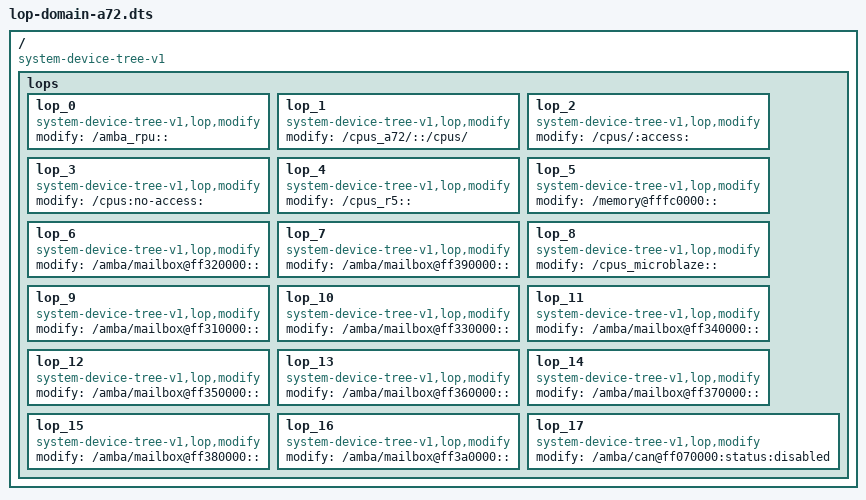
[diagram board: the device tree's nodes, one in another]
/*
 * Copyright (c) 2019,2020 Xilinx Inc. All rights reserved.
 *
 * Author:
 *       Bruce Ashfield <bruce.ashfield@xilinx.com>
 *
 * SPDX-License-Identifier: BSD-3-Clause
 */

/dts-v1/;

/ {
        compatible = "system-device-tree-v1";
        lops {
                // compatible = "system-device-tree-v1,lop";
                lop_0 {
                        // modify to "nothing", is a remove operation
                        compatible = "system-device-tree-v1,lop,modify";
                        modify = "/amba_rpu::";
                };
                lop_1 {
                        // node name modify
                        compatible = "system-device-tree-v1,lop,modify";
                        modify = "/cpus_a72/::/cpus/";
                };
                lop_2 {
                        compatible = "system-device-tree-v1,lop,modify";
                        // format is: "path":"property":"replacement"
                        //    - modify to "nothing", is a remove operation
                        //    - modify with no property is node operation (rename or remove)
                        modify = "/cpus/:access:";
                };
                lop_3 {
                        // modify to "nothing", is a remove operation
                        compatible = "system-device-tree-v1,lop,modify";
                        modify = "/cpus:no-access:";
                };
                lop_4 {
                        // modify to "nothing", is a remove operation
                        compatible = "system-device-tree-v1,lop,modify";
                        modify = "/cpus_r5::";
                };
                lop_5 {
                        // modify to "nothing", is a remove operation
                        compatible = "system-device-tree-v1,lop,modify";
                        modify = "/memory@fffc0000::";
                };
		lop_6 {
                        compatible = "system-device-tree-v1,lop,modify";
                        modify = "/amba/mailbox@ff320000::";
                };
		lop_7 {
                        compatible = "system-device-tree-v1,lop,modify";
                        modify = "/amba/mailbox@ff390000::";
                };
                lop_8 {
                        // modify to "nothing", is a remove operation
                        compatible = "system-device-tree-v1,lop,modify";
                        modify = "/cpus_microblaze::";
                };
		lop_9 {
                        compatible = "system-device-tree-v1,lop,modify";
                        modify = "/amba/mailbox@ff310000::";
                };
		lop_10 {
                        compatible = "system-device-tree-v1,lop,modify";
                        modify = "/amba/mailbox@ff330000::";
                };
		lop_11 {
                        compatible = "system-device-tree-v1,lop,modify";
                        modify = "/amba/mailbox@ff340000::";
                };
		lop_12 {
                        compatible = "system-device-tree-v1,lop,modify";
                        modify = "/amba/mailbox@ff350000::";
                };
		lop_13 {
                        compatible = "system-device-tree-v1,lop,modify";
                        modify = "/amba/mailbox@ff360000::";
                };
		lop_14 {
                        compatible = "system-device-tree-v1,lop,modify";
                        modify = "/amba/mailbox@ff370000::";
                };
		lop_15 {
                        compatible = "system-device-tree-v1,lop,modify";
                        modify = "/amba/mailbox@ff380000::";
                };
		lop_16 {
                        compatible = "system-device-tree-v1,lop,modify";
                        modify = "/amba/mailbox@ff3a0000::";
                };
		lop_17 {
                        compatible = "system-device-tree-v1,lop,modify";
                        modify = "/amba/can@ff070000:status:disabled";
                };
        };
};
